# SCR_TC3xx register map
Vendor: Infineon; File version: 1.0
Registers are 8-bit, read-write, reset 0x0 unless marked. A register's access mark holds for its fields unless they carry their own. Offsets are from the block's base; [hi:lo] are bit positions; 'fields as' and 'values as' point back to an identical list.

## SCR_T01 — SCR Timer 0 and timer 1
Base 0x00040000
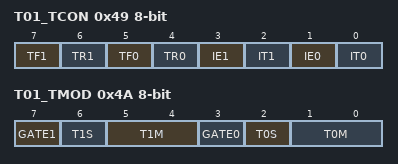
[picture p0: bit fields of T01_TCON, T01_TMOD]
0x49 T01_TCON — Timer 0/1 Control Register (SFR 0xC9)
  [7] TF1 — Timer 1 Overflow Flag. Set by hardware on Timer/Counter 1 overflow. Cleared by hardware when processor vectors to interrupt routine. Can also be set/cleared by software. Note:TF1 is set by TH0 instead, if Timer 0 operates in Mode 3. [rwh]
  [6] TR1 — Timer 1 Run Control. Note:Timer 1 Run Control also affects TH0, if Timer 0 operates in Mode 3. [rw]
    0=TIMER_IS_HALTED; 1=TIMER_RUNS
  [5] TF0 — Timer 0 Overflow Flag. Set by hardware on Timer/Counter 0 overflow. Cleared by hardware when processor vectors to interrupt routine. Can also be set/cleared by software. [rwh]
  [4] TR0 — Timer 0 Run Control. [rw]
    0=TIMER_IS_HALTED; 1=TIMER_RUNS
  [3] IE1 — External Interrupt 1 Flag. Set by hardware when external interrupt 1 event is detected. Cleared by hardware when the processor vectors to interrupt routine. Can also be set/cleared by software. [rwh]
  [2] IT1 — External Interrupt 1 Level/Edge Trigger Control. [rw]
    0=LOW_LEVEL_TRIGGERED_EXTERNAL (Low level triggered external interrupt 1 is selected); 1=FALLING_EDGE_TRIGGERED_EXTERNAL (Falling edge triggered external interrupt 1 is selected)
  [1] IE0 — External Interrupt 0 Flag. Set by hardware when external interrupt 0 event is detected. Cleared by hardware when the processor vectors to interrupt routine. Can also be set/cleared by software. [rwh]
  [0] IT0 — External Interrupt 0 Level/Edge Trigger Control. [rw]
    0=LOW_LEVEL_TRIGGERED_EXTERNAL (Low level triggered external interrupt 0 is selected); 1=FALLING_EDGE_TRIGGERED_EXTERNAL (Falling edge triggered external interrupt 0 is selected)
0x4A T01_TMOD — Timer Mode Register (SFR 0xCA)
  [7] GATE1 — Timer 1 Gate Control. [rw]
    0=TIMER_1_WILL_ONLY_RUN_IF_TCON_TR1 (Timer 1 will only run if TCON.TR1 = 1 (software control)); 1=TIMER_1_WILL_ONLY_RUN_IF_EXINT1 (Timer 1 will only run if EXINT1 pin = 1 (hardware control) and TCON.TR1 is set)
  [6] T1S — Timer 1 Input Selector. [rw]
    0=INPUT_IS_FROM_INTERNAL_SYSTEM (Input is from internal system clock); 1=INPUT_IS_FROM_T1_PIN
  [5:4] T1M — Timer 1 Mode Select Bits. [rw]
    0=TIMER_13B (13-bit timer (M8048 compatible mode)); 1=TIMER_16B (16-bit timer); 2=TIMER_8B_AUTO_REL (8-bit auto-reload timer); 3=TIMER0_SPLIT (Timer 0 is split into two halves. TL0 is an 8-bit timer controlled by the standard Timer 0 control bits, and TH0 is the other 8-bit timer controlled by the standard Timer 1 control bits. TH1 and TL1 of Timer 1 are held (Timer 1 is stopped).)
  [3] GATE0 — Timer 0 Gate Control. [rw]
    0=TIMER_0_WILL_ONLY_RUN_IF_TCON_TR0 (Timer 0 will only run if TCON.TR0 = 1 (software control)); 1=TIMER_0_WILL_ONLY_RUN_IF_EXINT0 (Timer 0 will only run if EXINT0 pin = 1 (hardware control) and TCON.TR0 is set)
  [2] T0S — Timer 0 Input Selector. [rw]
    0=INPUT_IS_FROM_INTERNAL_SYSTEM (Input is from internal system clock); 1=INPUT_IS_FROM_T0_PIN
  [1:0] T0M — Timer 0 Mode Select Bits. [rw]
    values as T1M
0x4B T01_TL0 — Timer 0 Low Byte (SFR 0xCB)
  [7:0] VAL — Timer 0 Low Byte Value. Note:If TMOD.T0M is equal to: 00B: TL0 holds the 5-bit prescaler value. 01B: TL0 holds the lower 8-bit part of the 16-bit timer value. 10B: TL0 holds the 8-bit timer value. 11B: TL0 holds the 8-bit timer value. [rwh]
0x4C T01_TL1 — Timer 1 Low Byte (SFR 0xCC)
  [7:0] VAL — Timer 1 Low Byte Value. Note:If TMOD.T1M is equal to: 00B: TL1 holds the 5-bit prescaler value. 01B: TL1 holds the lower 8-bit part of the 16-bit timer value. 10B: TL1 holds the 8-bit timer value. 11B: TL1 is not used. [rwh]
0x4D T01_TH0 — Timer 0 High Byte (SFR 0xCD)
  [7:0] VAL — Timer 0 High Byte Value. Note:If TMOD.T0M is equal to: 00B: TH0 holds the 8-bit prescaler value. 01B: TH0 holds the higher 8-bit part of the 16-bit timer value. 10B: TH0 holds the 8-bit reload value. 11B: TH0 holds the 8-bit timer value. [rwh]
0x4E T01_TH1 — Timer 1 High Byte (SFR 0xCE)
  [7:0] VAL — Timer 1 High Byte Value. Note:If TMOD.T1M is equal to: 00B: TH1 holds the 8-bit prescaler value. 01B: TH1 holds the higher 8-bit part of the 16-bit timer value. 10B: TH1 holds the 8-bit reload value. 11B: TH1 is not used. [rwh]
